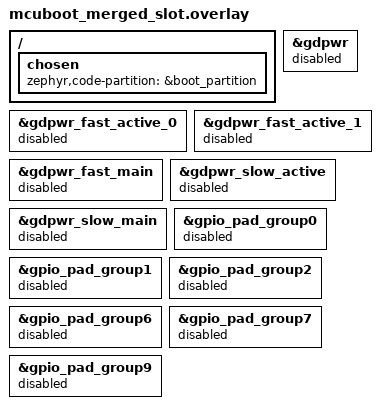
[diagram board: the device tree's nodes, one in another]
/*
 * Copyright (c) 2025 Nordic Semiconductor ASA
 *
 * SPDX-License-Identifier: LicenseRef-Nordic-5-Clause
 */

#include "nrf54h20dk_nrf54h20_memory_map_merged_slot.dtsi"

/ {
	chosen {
		zephyr,code-partition = &boot_partition;
	};
};

/*
 * Copy required overlay for mcuboot from bootloader/mcuboot.
 *
 * Required as the overlay in bootloader/mcuboot is ignored due to
 * FILE_SUFFIX="merged_slot" matching this overlay instead.
 */

&gdpwr {
	status = "disabled";
};

&gdpwr_fast_active_0 {
	status = "disabled";
};

&gdpwr_fast_active_1 {
	status = "disabled";
};

&gdpwr_fast_main {
	status = "disabled";
};

&gdpwr_slow_active {
	status = "disabled";
};

&gdpwr_slow_main {
	status = "disabled";
};

&gpio_pad_group0 {
	status = "disabled";
};

&gpio_pad_group1 {
	status = "disabled";
};

&gpio_pad_group2 {
	status = "disabled";
};

&gpio_pad_group6 {
	status = "disabled";
};

&gpio_pad_group7 {
	status = "disabled";
};

&gpio_pad_group9 {
	status = "disabled";
};
